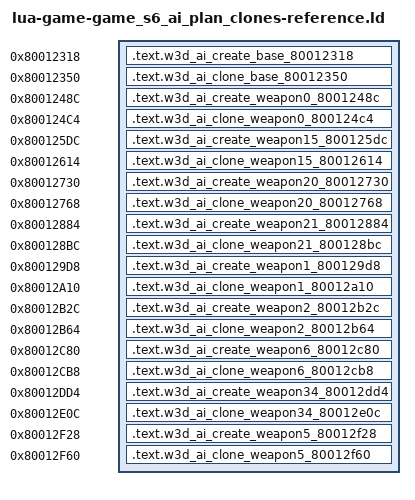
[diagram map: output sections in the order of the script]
/* Generated reference-only placements. All bodies are source-built. */
OUTPUT_FORMAT("elf32-powerpc")
OUTPUT_ARCH(powerpc)
ENTRY(w3d_ai_create_base_80012318)
_SDA_BASE_ = 0x804b2540;
_SDA2_BASE_ = 0x804c2540;
w3d_auto_8001523c = 0x8001523c;
w3d_f32_8036a478 = 0x8036a478;
w3d_f32_8036a494 = 0x8036a494;
w3d_f32_8036a498 = 0x8036a498;
w3d_f32_8036a49c = 0x8036a49c;
w3d_f32_8036a4a0 = 0x8036a4a0;
w3d_f32_8036a4a4 = 0x8036a4a4;
w3d_f32_8036a4a8 = 0x8036a4a8;
w3d_f32_8036a4ac = 0x8036a4ac;
w3d_f32_8036a4b0 = 0x8036a4b0;
w3d_f32_8036a4b4 = 0x8036a4b4;
w3d_path_cost_construct = 0x80006360;
w3d_vtable_8040d3e8 = 0x8040d3e8;
w3d_vtable_8040d428 = 0x8040d428;
w3d_vtable_8040d468 = 0x8040d468;
w3d_vtable_8040d4a8 = 0x8040d4a8;
w3d_vtable_8040d4e8 = 0x8040d4e8;
w3d_vtable_8040d528 = 0x8040d528;
w3d_vtable_8040d568 = 0x8040d568;
w3d_vtable_8040d5a8 = 0x8040d5a8;
w3d_vtable_8040d5e8 = 0x8040d5e8;
w3d_vtable_8040d780 = 0x8040d780;
w3d_vtable_8040d7b8 = 0x8040d7b8;
SECTIONS {
  .text.w3d_ai_create_base_80012318 0x80012318 : { *(.text.w3d_ai_create_base_80012318) }
  .text.w3d_ai_clone_base_80012350 0x80012350 : { *(.text.w3d_ai_clone_base_80012350) }
  .text.w3d_ai_create_weapon0_8001248c 0x8001248c : { *(.text.w3d_ai_create_weapon0_8001248c) }
  .text.w3d_ai_clone_weapon0_800124c4 0x800124c4 : { *(.text.w3d_ai_clone_weapon0_800124c4) }
  .text.w3d_ai_create_weapon15_800125dc 0x800125dc : { *(.text.w3d_ai_create_weapon15_800125dc) }
  .text.w3d_ai_clone_weapon15_80012614 0x80012614 : { *(.text.w3d_ai_clone_weapon15_80012614) }
  .text.w3d_ai_create_weapon20_80012730 0x80012730 : { *(.text.w3d_ai_create_weapon20_80012730) }
  .text.w3d_ai_clone_weapon20_80012768 0x80012768 : { *(.text.w3d_ai_clone_weapon20_80012768) }
  .text.w3d_ai_create_weapon21_80012884 0x80012884 : { *(.text.w3d_ai_create_weapon21_80012884) }
  .text.w3d_ai_clone_weapon21_800128bc 0x800128bc : { *(.text.w3d_ai_clone_weapon21_800128bc) }
  .text.w3d_ai_create_weapon1_800129d8 0x800129d8 : { *(.text.w3d_ai_create_weapon1_800129d8) }
  .text.w3d_ai_clone_weapon1_80012a10 0x80012a10 : { *(.text.w3d_ai_clone_weapon1_80012a10) }
  .text.w3d_ai_create_weapon2_80012b2c 0x80012b2c : { *(.text.w3d_ai_create_weapon2_80012b2c) }
  .text.w3d_ai_clone_weapon2_80012b64 0x80012b64 : { *(.text.w3d_ai_clone_weapon2_80012b64) }
  .text.w3d_ai_create_weapon6_80012c80 0x80012c80 : { *(.text.w3d_ai_create_weapon6_80012c80) }
  .text.w3d_ai_clone_weapon6_80012cb8 0x80012cb8 : { *(.text.w3d_ai_clone_weapon6_80012cb8) }
  .text.w3d_ai_create_weapon34_80012dd4 0x80012dd4 : { *(.text.w3d_ai_create_weapon34_80012dd4) }
  .text.w3d_ai_clone_weapon34_80012e0c 0x80012e0c : { *(.text.w3d_ai_clone_weapon34_80012e0c) }
  .text.w3d_ai_create_weapon5_80012f28 0x80012f28 : { *(.text.w3d_ai_create_weapon5_80012f28) }
  .text.w3d_ai_clone_weapon5_80012f60 0x80012f60 : { *(.text.w3d_ai_clone_weapon5_80012f60) }
  /DISCARD/ : { *(.text*) *(.rodata*) *(.data*) *(.bss*) *(.sdata*) *(.sbss*) *(.comment) }
}
